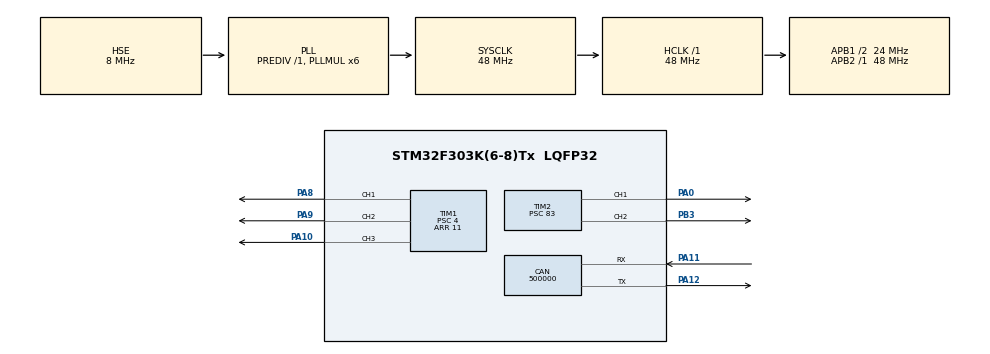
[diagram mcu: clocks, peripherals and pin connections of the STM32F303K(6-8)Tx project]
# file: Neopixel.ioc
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CAN.CalculateBaudRate=500000
CAN.CalculateTimeBit=2000
CAN.CalculateTimeQuantum=666.6666666666666
Dma.Request0=TIM2_CH1
Dma.Request1=TIM1_CH1
Dma.Request2=TIM1_CH2
Dma.Request3=TIM1_CH3
Dma.TIM1_CH1.1.Direction=DMA_MEMORY_TO_PERIPH
Dma.TIM1_CH1.1.Instance=DMA1_Channel2
Dma.TIM1_CH1.1.MemDataAlignment=DMA_MDATAALIGN_BYTE
Dma.TIM1_CH1.1.MemInc=DMA_MINC_ENABLE
Dma.TIM1_CH1.1.Mode=DMA_CIRCULAR
Dma.TIM1_CH1.1.PeriphDataAlignment=DMA_PDATAALIGN_HALFWORD
Dma.TIM1_CH1.1.PeriphInc=DMA_PINC_DISABLE
Dma.TIM1_CH1.1.Priority=DMA_PRIORITY_LOW
Dma.TIM1_CH2.2.Direction=DMA_MEMORY_TO_PERIPH
Dma.TIM1_CH2.2.Instance=DMA1_Channel3
Dma.TIM1_CH2.2.MemDataAlignment=DMA_MDATAALIGN_BYTE
Dma.TIM1_CH2.2.MemInc=DMA_MINC_ENABLE
Dma.TIM1_CH2.2.Mode=DMA_CIRCULAR
Dma.TIM1_CH2.2.PeriphDataAlignment=DMA_PDATAALIGN_HALFWORD
Dma.TIM1_CH2.2.PeriphInc=DMA_PINC_DISABLE
Dma.TIM1_CH2.2.Priority=DMA_PRIORITY_LOW
Dma.TIM1_CH3.3.Direction=DMA_MEMORY_TO_PERIPH
Dma.TIM1_CH3.3.Instance=DMA1_Channel6
Dma.TIM1_CH3.3.MemDataAlignment=DMA_MDATAALIGN_BYTE
Dma.TIM1_CH3.3.MemInc=DMA_MINC_ENABLE
Dma.TIM1_CH3.3.Mode=DMA_CIRCULAR
Dma.TIM1_CH3.3.PeriphDataAlignment=DMA_PDATAALIGN_HALFWORD
Dma.TIM1_CH3.3.PeriphInc=DMA_PINC_DISABLE
Dma.TIM1_CH3.3.Priority=DMA_PRIORITY_LOW
Dma.TIM2_CH1.0.Direction=DMA_MEMORY_TO_PERIPH
Dma.TIM2_CH1.0.Instance=DMA1_Channel5
Dma.TIM2_CH1.0.MemDataAlignment=DMA_MDATAALIGN_BYTE
Dma.TIM2_CH1.0.MemInc=DMA_MINC_ENABLE
Dma.TIM2_CH1.0.Mode=DMA_CIRCULAR
Dma.TIM2_CH1.0.PeriphDataAlignment=DMA_PDATAALIGN_WORD
Dma.TIM2_CH1.0.PeriphInc=DMA_PINC_DISABLE
Dma.TIM2_CH1.0.Priority=DMA_PRIORITY_LOW
Mcu.Family=STM32F3
Mcu.Name=STM32F303K(6-8)Tx
Mcu.Package=LQFP32
NVIC.DMA1_Channel2_IRQn=true\:0\:0\:false\:false\:true\:false\:true\:true
NVIC.DMA1_Channel3_IRQn=true\:0\:0\:false\:false\:true\:false\:true\:true
NVIC.DMA1_Channel5_IRQn=true\:0\:0\:false\:false\:true\:false\:true\:true
NVIC.DMA1_Channel6_IRQn=true\:0\:0\:false\:false\:true\:false\:true\:true
NVIC.PriorityGroup=NVIC_PRIORITYGROUP_4
PA0.GPIO_Speed=GPIO_SPEED_FREQ_HIGH
PA0.Signal=S_TIM2_CH1_ETR
PA10.GPIO_Speed=GPIO_SPEED_FREQ_HIGH
PA10.Signal=S_TIM1_CH3
PA11.Mode=CAN_Activate
PA11.Signal=CAN_RX
PA12.Mode=CAN_Activate
PA12.Signal=CAN_TX
PA13.GPIO_Label=SWDIO
PA13.Mode=Serial_Wire
PA13.Signal=SYS_JTMS-SWDIO
PA14.GPIO_Label=SWCLK
PA14.Mode=Serial_Wire
PA14.Signal=SYS_JTCK-SWCLK
PA8.GPIO_Speed=GPIO_SPEED_FREQ_HIGH
PA8.Signal=S_TIM1_CH1
PA9.GPIO_Speed=GPIO_SPEED_FREQ_HIGH
PA9.Signal=S_TIM1_CH2
PB3.Signal=S_TIM2_CH2
PF0\ /\ OSC_IN.GPIO_Label=MCO
PF0\ /\ OSC_IN.Mode=HSE-External-Clock-Source
PF0\ /\ OSC_IN.Signal=RCC_OSC_IN
ProjectManager.HeapSize=0x200
ProjectManager.StackSize=0x400
ProjectManager.TargetToolchain=EWARM V8.32
RCC.AHBFreq_Value=48000000
RCC.APB1CLKDivider=RCC_HCLK_DIV2
RCC.APB1Freq_Value=24000000
RCC.APB1TimFreq_Value=48000000
RCC.APB2Freq_Value=48000000
RCC.APB2TimFreq_Value=48000000
RCC.CortexFreq_Value=48000000
RCC.HCLKFreq_Value=48000000
RCC.HSE_VALUE=8000000
RCC.HSI_VALUE=8000000
RCC.PLLMUL=RCC_PLL_MUL6
RCC.PLLSourceVirtual=RCC_PLLSOURCE_HSE
RCC.SYSCLKFreq_VALUE=48000000
RCC.SYSCLKSourceVirtual=RCC_SYSCLKSOURCE_PLLCLK
SH.S_TIM1_CH1.0=TIM1_CH1,PWM Generation1 CH1
SH.S_TIM1_CH2.0=TIM1_CH2,PWM Generation2 CH2
SH.S_TIM1_CH3.0=TIM1_CH3,PWM Generation3 CH3
SH.S_TIM2_CH1_ETR.0=TIM2_CH1,PWM Generation1 CH1
SH.S_TIM2_CH2.0=TIM2_CH2,PWM Generation2 CH2
TIM1.AutoReloadPreload=TIM_AUTORELOAD_PRELOAD_ENABLE
TIM1.Channel-PWM\ Generation1\ CH1=TIM_CHANNEL_1
TIM1.Channel-PWM\ Generation2\ CH2=TIM_CHANNEL_2
TIM1.Channel-PWM\ Generation3\ CH3=TIM_CHANNEL_3
TIM1.OCFastMode_PWM-PWM\ Generation1\ CH1=TIM_OCFAST_ENABLE
TIM1.OCFastMode_PWM-PWM\ Generation2\ CH2=TIM_OCFAST_ENABLE
TIM1.OCFastMode_PWM-PWM\ Generation3\ CH3=TIM_OCFAST_ENABLE
TIM1.Period=11
TIM1.Prescaler=4
TIM1.TIM_MasterOutputTrigger=TIM_TRGO_OC1REF
TIM1.TIM_MasterOutputTrigger2=TIM_TRGO2_OC1REF
TIM1.TIM_MasterSlaveMode=TIM_MASTERSLAVEMODE_ENABLE
TIM2.AutoReloadPreload=TIM_AUTORELOAD_PRELOAD_ENABLE
TIM2.Channel-PWM\ Generation1\ CH1=TIM_CHANNEL_1
TIM2.Channel-PWM\ Generation2\ CH2=TIM_CHANNEL_2
TIM2.OCFastMode_PWM-PWM\ Generation1\ CH1=TIM_OCFAST_ENABLE
TIM2.Period=999
TIM2.Prescaler=83
TIM2.TIM_MasterOutputTrigger=TIM_TRGO_OC1REF
TIM2.TIM_MasterSlaveMode=TIM_MASTERSLAVEMODE_ENABLE
VP_TIM1_VS_ClockSourceINT.Mode=Internal
VP_TIM2_VS_ClockSourceINT.Mode=Internal
board=NUCLEO-F303K8

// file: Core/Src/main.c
/* USER CODE BEGIN Header */
/**
  ******************************************************************************
  * @file           : main.c
  * @brief          : Main program body
  ******************************************************************************
  * @attention
  *
  * Copyright (c) 2023 STMicroelectronics.
  * All rights reserved.
  *
  * This software is licensed under terms that can be found in the LICENSE file
  * in the root directory of this software component.
  * If no LICENSE file comes with this software, it is provided AS-IS.
  *
  ******************************************************************************
  */
/* USER CODE END Header */
#include "main.h"

CAN_HandleTypeDef hcan;

TIM_HandleTypeDef htim1;
TIM_HandleTypeDef htim2;
DMA_HandleTypeDef hdma_tim1_ch1;
DMA_HandleTypeDef hdma_tim1_ch2;
DMA_HandleTypeDef hdma_tim1_ch3;
DMA_HandleTypeDef hdma_tim2_ch1;

void SystemClock_Config(void);
static void MX_GPIO_Init(void);
static void MX_DMA_Init(void);
static void MX_CAN_Init(void);
static void MX_TIM1_Init(void);
static void MX_TIM2_Init(void);

int main(void)
{

  /* MCU Configuration--------------------------------------------------------*/

  /* Reset of all peripherals, Initializes the Flash interface and the Systick. */
  HAL_Init();

  /* USER CODE BEGIN Init */
  uint8_t  rgb[] = {
    0x44, 0x88, 0x88,
  };

  /* USER CODE END Init */

  /* Configure the system clock */
  SystemClock_Config();

  /* Initialize all configured peripherals */
  MX_GPIO_Init();
  MX_DMA_Init();
  MX_CAN_Init();
  MX_TIM1_Init();
  MX_TIM2_Init();
  /* USER CODE BEGIN 2 */
  NeoPixInit(&htim1, TIM_CHANNEL_1);
  NeoPixInit(&htim2, TIM_CHANNEL_1);
  NeoPixStart(rgb, sizeof (rgb));
  /* USER CODE END 2 */

  /* Infinite loop */
  while (1)
  {

  }
}

void SystemClock_Config(void)
{
  RCC_OscInitTypeDef RCC_OscInitStruct = {0};
  RCC_ClkInitTypeDef RCC_ClkInitStruct = {0};
  RCC_PeriphCLKInitTypeDef PeriphClkInit = {0};

  /** Initializes the RCC Oscillators according to the specified parameters
  * in the RCC_OscInitTypeDef structure.
  */
  RCC_OscInitStruct.OscillatorType = RCC_OSCILLATORTYPE_HSE;
  RCC_OscInitStruct.HSEState = RCC_HSE_BYPASS;
  RCC_OscInitStruct.HSEPredivValue = RCC_HSE_PREDIV_DIV1;
  RCC_OscInitStruct.HSIState = RCC_HSI_ON;
  RCC_OscInitStruct.PLL.PLLState = RCC_PLL_ON;
  RCC_OscInitStruct.PLL.PLLSource = RCC_PLLSOURCE_HSE;
  RCC_OscInitStruct.PLL.PLLMUL = RCC_PLL_MUL6;
  if (HAL_RCC_OscConfig(&RCC_OscInitStruct) != HAL_OK)
  {
    Error_Handler();
  }

  /** Initializes the CPU, AHB and APB buses clocks
  */
  RCC_ClkInitStruct.ClockType = RCC_CLOCKTYPE_HCLK|RCC_CLOCKTYPE_SYSCLK
                              |RCC_CLOCKTYPE_PCLK1|RCC_CLOCKTYPE_PCLK2;
  RCC_ClkInitStruct.SYSCLKSource = RCC_SYSCLKSOURCE_PLLCLK;
  RCC_ClkInitStruct.AHBCLKDivider = RCC_SYSCLK_DIV1;
  RCC_ClkInitStruct.APB1CLKDivider = RCC_HCLK_DIV2;
  RCC_ClkInitStruct.APB2CLKDivider = RCC_HCLK_DIV1;

  if (HAL_RCC_ClockConfig(&RCC_ClkInitStruct, FLASH_LATENCY_1) != HAL_OK)
  {
    Error_Handler();
  }
  PeriphClkInit.PeriphClockSelection = RCC_PERIPHCLK_TIM1;
  PeriphClkInit.Tim1ClockSelection = RCC_TIM1CLK_HCLK;
  if (HAL_RCCEx_PeriphCLKConfig(&PeriphClkInit) != HAL_OK)
  {
    Error_Handler();
  }
}

static void MX_CAN_Init(void)
{

  hcan.Instance = CAN;
  hcan.Init.Prescaler = 16;
  hcan.Init.Mode = CAN_MODE_NORMAL;
  hcan.Init.SyncJumpWidth = CAN_SJW_1TQ;
  hcan.Init.TimeSeg1 = CAN_BS1_1TQ;
  hcan.Init.TimeSeg2 = CAN_BS2_1TQ;
  hcan.Init.TimeTriggeredMode = DISABLE;
  hcan.Init.AutoBusOff = DISABLE;
  hcan.Init.AutoWakeUp = DISABLE;
  hcan.Init.AutoRetransmission = DISABLE;
  hcan.Init.ReceiveFifoLocked = DISABLE;
  hcan.Init.TransmitFifoPriority = DISABLE;
  if (HAL_CAN_Init(&hcan) != HAL_OK)
  {
    Error_Handler();
  }

}

static void MX_TIM1_Init(void)
{

  TIM_ClockConfigTypeDef sClockSourceConfig = {0};
  TIM_MasterConfigTypeDef sMasterConfig = {0};
  TIM_OC_InitTypeDef sConfigOC = {0};
  TIM_BreakDeadTimeConfigTypeDef sBreakDeadTimeConfig = {0};

  htim1.Instance = TIM1;
  htim1.Init.Prescaler = 4;
  htim1.Init.CounterMode = TIM_COUNTERMODE_UP;
  htim1.Init.Period = 11;
  htim1.Init.ClockDivision = TIM_CLOCKDIVISION_DIV1;
  htim1.Init.RepetitionCounter = 0;
  htim1.Init.AutoReloadPreload = TIM_AUTORELOAD_PRELOAD_ENABLE;
  if (HAL_TIM_Base_Init(&htim1) != HAL_OK)
  {
    Error_Handler();
  }
  sClockSourceConfig.ClockSource = TIM_CLOCKSOURCE_INTERNAL;
  if (HAL_TIM_ConfigClockSource(&htim1, &sClockSourceConfig) != HAL_OK)
  {
    Error_Handler();
  }
  if (HAL_TIM_PWM_Init(&htim1) != HAL_OK)
  {
    Error_Handler();
  }
  sMasterConfig.MasterOutputTrigger = TIM_TRGO_OC1REF;
  sMasterConfig.MasterOutputTrigger2 = TIM_TRGO2_OC1REF;
  sMasterConfig.MasterSlaveMode = TIM_MASTERSLAVEMODE_ENABLE;
  if (HAL_TIMEx_MasterConfigSynchronization(&htim1, &sMasterConfig) != HAL_OK)
  {
    Error_Handler();
  }
  sConfigOC.OCMode = TIM_OCMODE_PWM1;
  sConfigOC.Pulse = 0;
  sConfigOC.OCPolarity = TIM_OCPOLARITY_HIGH;
  sConfigOC.OCNPolarity = TIM_OCNPOLARITY_HIGH;
  sConfigOC.OCFastMode = TIM_OCFAST_ENABLE;
  sConfigOC.OCIdleState = TIM_OCIDLESTATE_RESET;
  sConfigOC.OCNIdleState = TIM_OCNIDLESTATE_RESET;
  if (HAL_TIM_PWM_ConfigChannel(&htim1, &sConfigOC, TIM_CHANNEL_1) != HAL_OK)
  {
    Error_Handler();
  }
  if (HAL_TIM_PWM_ConfigChannel(&htim1, &sConfigOC, TIM_CHANNEL_2) != HAL_OK)
  {
    Error_Handler();
  }
  if (HAL_TIM_PWM_ConfigChannel(&htim1, &sConfigOC, TIM_CHANNEL_3) != HAL_OK)
  {
    Error_Handler();
  }
  sBreakDeadTimeConfig.OffStateRunMode = TIM_OSSR_DISABLE;
  sBreakDeadTimeConfig.OffStateIDLEMode = TIM_OSSI_DISABLE;
  sBreakDeadTimeConfig.LockLevel = TIM_LOCKLEVEL_OFF;
  sBreakDeadTimeConfig.DeadTime = 0;
  sBreakDeadTimeConfig.BreakState = TIM_BREAK_DISABLE;
  sBreakDeadTimeConfig.BreakPolarity = TIM_BREAKPOLARITY_HIGH;
  sBreakDeadTimeConfig.BreakFilter = 0;
  sBreakDeadTimeConfig.Break2State = TIM_BREAK2_DISABLE;
  sBreakDeadTimeConfig.Break2Polarity = TIM_BREAK2POLARITY_HIGH;
  sBreakDeadTimeConfig.Break2Filter = 0;
  sBreakDeadTimeConfig.AutomaticOutput = TIM_AUTOMATICOUTPUT_DISABLE;
  if (HAL_TIMEx_ConfigBreakDeadTime(&htim1, &sBreakDeadTimeConfig) != HAL_OK)
  {
    Error_Handler();
  }
  HAL_TIM_MspPostInit(&htim1);

}

static void MX_TIM2_Init(void)
{

  TIM_ClockConfigTypeDef sClockSourceConfig = {0};
  TIM_MasterConfigTypeDef sMasterConfig = {0};
  TIM_OC_InitTypeDef sConfigOC = {0};

  htim2.Instance = TIM2;
  htim2.Init.Prescaler = 5;
  htim2.Init.CounterMode = TIM_COUNTERMODE_UP;
  htim2.Init.Period = 9;
  htim2.Init.ClockDivision = TIM_CLOCKDIVISION_DIV1;
  htim2.Init.AutoReloadPreload = TIM_AUTORELOAD_PRELOAD_ENABLE;
  if (HAL_TIM_Base_Init(&htim2) != HAL_OK)
  {
    Error_Handler();
  }
  sClockSourceConfig.ClockSource = TIM_CLOCKSOURCE_INTERNAL;
  if (HAL_TIM_ConfigClockSource(&htim2, &sClockSourceConfig) != HAL_OK)
  {
    Error_Handler();
  }
  if (HAL_TIM_PWM_Init(&htim2) != HAL_OK)
  {
    Error_Handler();
  }
  sMasterConfig.MasterOutputTrigger = TIM_TRGO_OC1REF;
  sMasterConfig.MasterSlaveMode = TIM_MASTERSLAVEMODE_ENABLE;
  if (HAL_TIMEx_MasterConfigSynchronization(&htim2, &sMasterConfig) != HAL_OK)
  {
    Error_Handler();
  }
  sConfigOC.OCMode = TIM_OCMODE_PWM1;
  sConfigOC.Pulse = 0;
  sConfigOC.OCPolarity = TIM_OCPOLARITY_HIGH;
  sConfigOC.OCFastMode = TIM_OCFAST_ENABLE;
  if (HAL_TIM_PWM_ConfigChannel(&htim2, &sConfigOC, TIM_CHANNEL_1) != HAL_OK)
  {
    Error_Handler();
  }
  HAL_TIM_MspPostInit(&htim2);

}

static void MX_DMA_Init(void)
{

  /* DMA controller clock enable */
  __HAL_RCC_DMA1_CLK_ENABLE();

  /* DMA interrupt init */
  /* DMA1_Channel2_IRQn interrupt configuration */
  HAL_NVIC_SetPriority(DMA1_Channel2_IRQn, 0, 0);
  HAL_NVIC_EnableIRQ(DMA1_Channel2_IRQn);
  /* DMA1_Channel3_IRQn interrupt configuration */
  HAL_NVIC_SetPriority(DMA1_Channel3_IRQn, 0, 0);
  HAL_NVIC_EnableIRQ(DMA1_Channel3_IRQn);
  /* DMA1_Channel5_IRQn interrupt configuration */
  HAL_NVIC_SetPriority(DMA1_Channel5_IRQn, 0, 0);
  HAL_NVIC_EnableIRQ(DMA1_Channel5_IRQn);
  /* DMA1_Channel6_IRQn interrupt configuration */
  HAL_NVIC_SetPriority(DMA1_Channel6_IRQn, 0, 0);
  HAL_NVIC_EnableIRQ(DMA1_Channel6_IRQn);

}

static void MX_GPIO_Init(void)
{

  /* GPIO Ports Clock Enable */
  __HAL_RCC_GPIOF_CLK_ENABLE();
  __HAL_RCC_GPIOA_CLK_ENABLE();

}

void Error_Handler(void)
{
  __disable_irq();
  while (1)
  {
  }
}
